VERSION ""

NS_ :

BS_:

BU_: Pi SlaveController

BO_ 10 BatterUniqueId: 8 SlaveController
 SG_ BatteryUniqueId_v2 : 0|64@1+ (1,0) [0|0] "" Vector__XXX

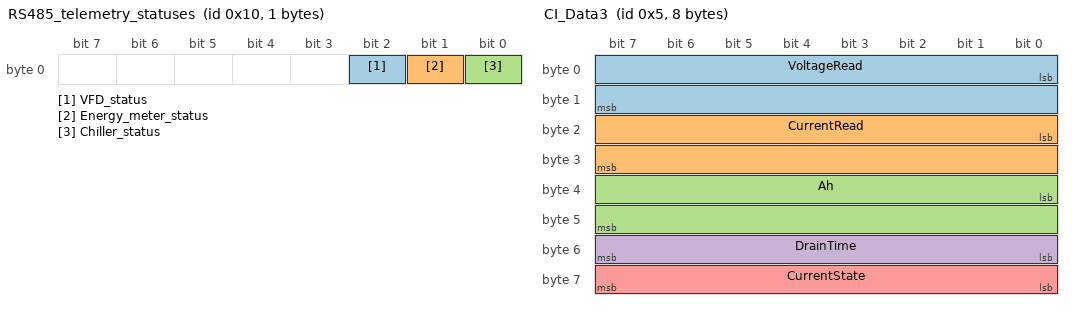
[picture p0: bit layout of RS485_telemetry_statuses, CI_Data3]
BO_ 16 RS485_telemetry_statuses: 1 SlaveController
 SG_ VFD_status : 2|1@1+ (1,0) [0|0] "" Vector__XXX
 SG_ Energy_meter_status : 1|1@1+ (1,0) [0|0] "" Vector__XXX
 SG_ Chiller_status : 0|1@1+ (1,0) [0|0] "" Vector__XXX

BO_ 5 CI_Data3: 8 SlaveController
 SG_ VoltageRead : 0|16@1+ (0.01,0) [0|0] "" Vector__XXX
 SG_ CurrentRead : 16|16@1+ (0.01,0) [0|0] "" Vector__XXX
 SG_ Ah : 32|16@1+ (0.01,0) [0|0] "" Vector__XXX
 SG_ DrainTime : 48|8@1+ (1,0) [0|0] "" Vector__XXX
 SG_ CurrentState : 56|8@1+ (1,0) [0|0] "" Vector__XXX

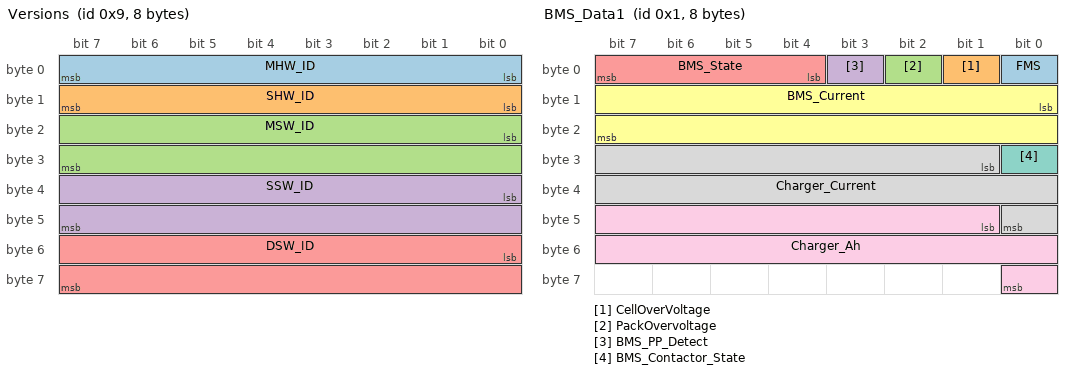
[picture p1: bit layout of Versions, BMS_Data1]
BO_ 9 Versions: 8 SlaveController
 SG_ MHW_ID : 0|8@1+ (1,0) [0|0] "" Vector__XXX
 SG_ SHW_ID : 8|8@1+ (1,0) [0|0] "" Vector__XXX
 SG_ MSW_ID : 16|16@1+ (1,0) [0|0] "" Vector__XXX
 SG_ SSW_ID : 32|16@1+ (1,0) [0|0] "" Vector__XXX
 SG_ DSW_ID : 48|16@1+ (1,0) [0|0] "" Vector__XXX

BO_ 1 BMS_Data1: 8 SlaveController
 SG_ FMS : 0|1@1+ (1,0) [0|0] "" Vector__XXX
 SG_ CellOverVoltage : 1|1@1+ (1,0) [0|0] "" Vector__XXX
 SG_ PackOvervoltage : 2|1@1+ (1,0) [0|0] "" Vector__XXX
 SG_ BMS_PP_Detect : 3|1@1+ (1,0) [0|0] "" Vector__XXX
 SG_ BMS_State : 4|4@1+ (1,0) [0|0] "" Vector__XXX
 SG_ BMS_Current : 8|16@1+ (0.1,-600) [0|0] "" Vector__XXX
 SG_ BMS_Contactor_State : 24|1@1+ (1,0) [0|0] "" Vector__XXX
 SG_ Charger_Current : 25|16@1+ (0.1,-600) [0|0] "" Vector__XXX
 SG_ Charger_Ah : 41|16@1+ (0.1,0) [0|0] "" Vector__XXX

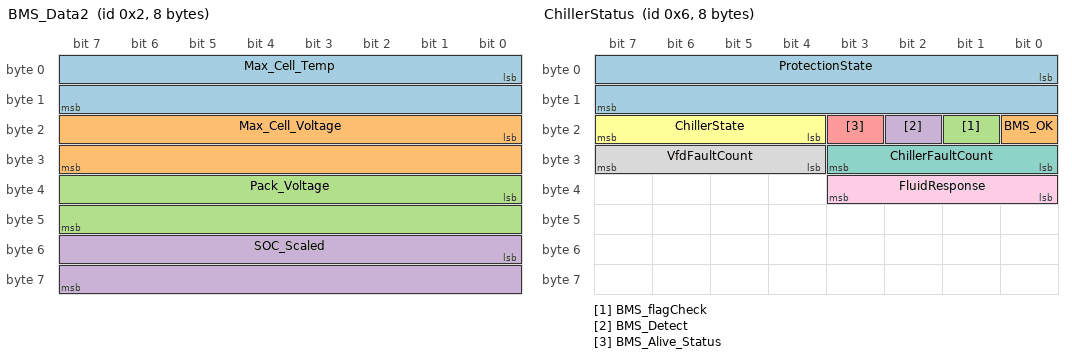
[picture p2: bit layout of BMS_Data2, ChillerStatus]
BO_ 2 BMS_Data2: 8 SlaveController
 SG_ Max_Cell_Temp : 0|16@1+ (0.01,-100) [0|0] "" Vector__XXX
 SG_ Max_Cell_Voltage : 16|16@1+ (0.0001,0) [0|0] "" Vector__XXX
 SG_ Pack_Voltage : 32|16@1+ (0.01,0) [0|0] "" Vector__XXX
 SG_ SOC_Scaled : 48|16@1+ (1.0,0) [0|0] "" Vector__XXX

BO_ 6 ChillerStatus: 8 SlaveController
 SG_ ProtectionState : 0|16@1+ (1,0) [0|0] "" Vector__XXX
 SG_ BMS_OK : 16|1@1+ (1,0) [0|0] "" Vector__XXX
 SG_ BMS_flagCheck : 17|1@1+ (1,0) [0|0] "" Vector__XXX
 SG_ BMS_Detect : 18|1@1+ (1,0) [0|0] "" Vector__XXX
 SG_ BMS_Alive_Status : 19|1@1+ (1,0) [0|0] "" Vector__XXX
 SG_ ChillerState : 20|4@1+ (1,0) [0|0] "" Vector__XXX
 SG_ ChillerFaultCount : 24|4@1+ (1,0) [0|0] "" Vector__XXX
 SG_ VfdFaultCount : 28|4@1+ (1,0) [0|0] "" Vector__XXX
 SG_ FluidResponse : 32|4@1+ (1,0) [0|0] "" Vector__XXX

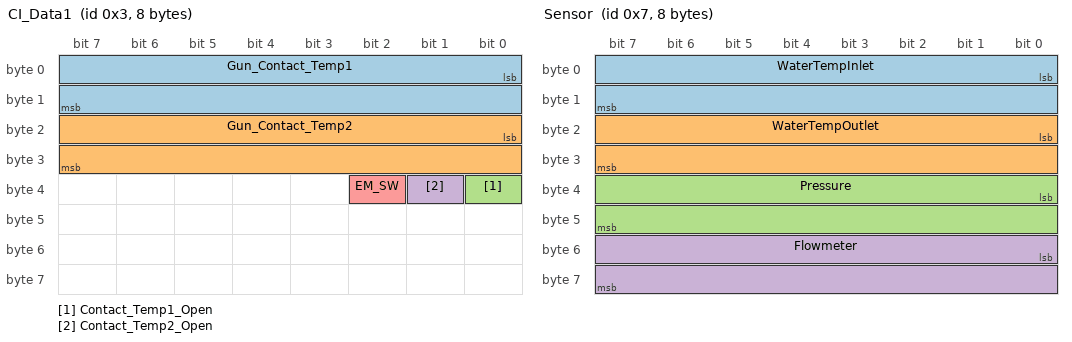
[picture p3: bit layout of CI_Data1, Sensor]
BO_ 3 CI_Data1: 8 SlaveController
 SG_ Gun_Contact_Temp1 : 0|16@1+ (0.01,-100) [0|0] "" Vector__XXX
 SG_ Gun_Contact_Temp2 : 16|16@1+ (0.01,-100) [0|0] "" Vector__XXX
 SG_ Contact_Temp1_Open : 32|1@1+ (1,0) [0|0] "" Vector__XXX
 SG_ Contact_Temp2_Open : 33|1@1+ (1,0) [0|0] "" Vector__XXX
 SG_ EM_SW : 34|1@1+ (1,0) [0|0] "" Vector__XXX

BO_ 4 CI_Data2: 8 SlaveController
 SG_ VoltageRef : 0|16@1+ (0.01,0) [0|0] "" Vector__XXX
 SG_ CurrentRef : 16|16@1+ (0.01,0) [0|0] "" Vector__XXX
 SG_ CC_ON : 32|1@1+ (1,0) [0|0] "" Vector__XXX
 SG_ DrainPump : 33|1@1+ (1,0) [0|0] "" Vector__XXX
 SG_ SolenoidA : 34|1@1+ (1,0) [0|0] "" Vector__XXX
 SG_ SolenoidB : 35|1@1+ (1,0) [0|0] "" Vector__XXX
 SG_ PositiveCont : 36|1@1+ (1,0) [0|0] "" Vector__XXX
 SG_ GunLock : 37|1@1+ (1,0) [0|0] "" Vector__XXX
 SG_ SolenoidC : 38|1@1+ (1,0) [0|0] "" Vector__XXX
 SG_ Precharge : 39|1@1+ (1,0) [0|0] "" Vector__XXX
 SG_ SolenoidA1 : 40|1@1+ (1,0) [0|0] "" Vector__XXX
 SG_ VFD_On : 41|1@1+ (1,0) [0|0] "" Vector__XXX
 SG_ Override : 42|1@1+ (1,0) [0|0] "" Vector__XXX
 SG_ AC_Cont : 43|1@1+ (1,0) [0|0] "" Vector__XXX
 SG_ SPD : 44|1@1+ (1,0) [0|0] "" Vector__XXX
 SG_ ELR : 45|1@1+ (1,0) [0|0] "" Vector__XXX
 SG_ VoltageRelay : 46|1@1+ (1,0) [0|0] "" Vector__XXX
 SG_ GunLockFB : 47|1@1+ (1,0) [0|0] "" Vector__XXX
 SG_ SolenoidB1 : 48|1@1+ (1,0) [0|0] "" Vector__XXX
 SG_ DisplayAlive : 49|1@1+ (1,0) [0|0] "" Vector__XXX
 SG_ MasterHearBeat : 50|1@1+ (1,0) [0|0] "" Vector__XXX
 SG_ SlaveHeartBeat : 51|1@1+ (1,0) [0|0] "" Vector__XXX

BO_ 7 Sensor: 8 SlaveController
 SG_ WaterTempInlet : 0|16@1+ (0.1,0) [0|0] "" Vector__XXX
 SG_ WaterTempOutlet : 16|16@1+ (0.1,0) [0|0] "" Vector__XXX
 SG_ Pressure : 32|16@1+ (0.1,0) [0|0] "" Vector__XXX
 SG_ Flowmeter : 48|16@1+ (0.1,0) [0|0] "" Vector__XXX

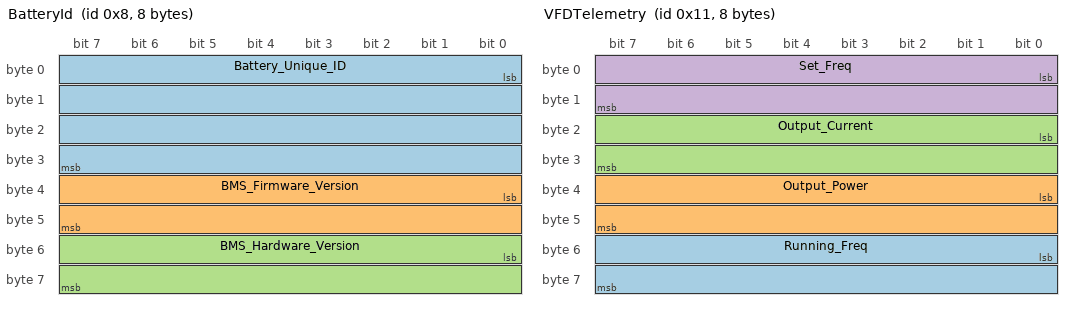
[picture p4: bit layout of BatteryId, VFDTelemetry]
BO_ 8 BatteryId: 8 SlaveController
 SG_ Battery_Unique_ID : 0|32@1+ (1,0) [0|0] "" Vector__XXX
 SG_ BMS_Firmware_Version : 32|16@1+ (1,0) [0|0] "" Vector__XXX
 SG_ BMS_Hardware_Version : 48|16@1+ (1,0) [0|0] "" Vector__XXX

BO_ 17 VFDTelemetry: 8 Pi
 SG_ Running_Freq : 48|16@1+ (0.01,0) [0|0] "Hz" Vector__XXX
 SG_ Output_Power : 32|16@1+ (0.1,0) [0|0] "kW" Vector__XXX
 SG_ Output_Current : 16|16@1+ (0.1,0) [0|0] "A" Vector__XXX
 SG_ Set_Freq : 0|16@1+ (0.01,0) [0|0] "Hz" Vector__XXX

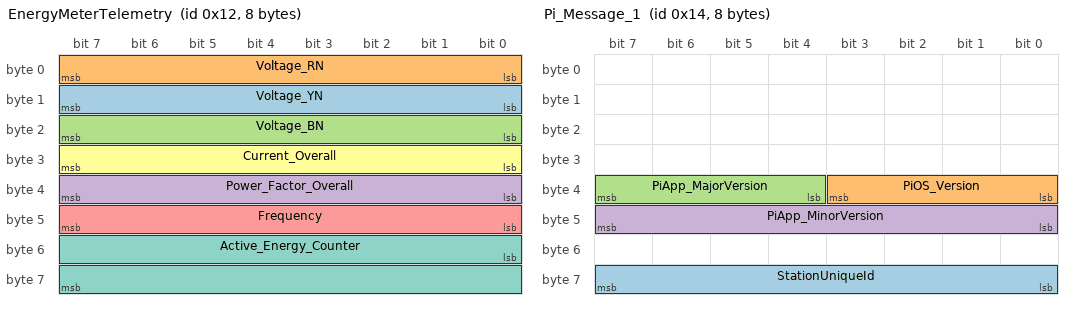
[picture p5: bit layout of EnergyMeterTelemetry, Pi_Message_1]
BO_ 18 EnergyMeterTelemetry: 8 Pi
 SG_ Voltage_YN : 8|8@1+ (2,0) [0|0] "V" Vector__XXX
 SG_ Voltage_RN : 0|8@1+ (2,0) [0|0] "V" Vector__XXX
 SG_ Voltage_BN : 16|8@1+ (2,0) [0|0] "V" Vector__XXX
 SG_ Power_Factor_Overall : 32|8@1- (0.01,0) [0|0] "" Vector__XXX
 SG_ Frequency : 40|8@1- (0.01,50) [0|0] "Hz" Vector__XXX
 SG_ Current_Overall : 24|8@1+ (1,0) [0|0] "A" Vector__XXX
 SG_ Active_Energy_Counter : 48|16@1- (1,0) [0|0] "kWh" Vector__XXX

BO_ 19 ChillerTelemetry: 8 Pi
 SG_ SV_On : 58|1@1+ (1,0) [0|0] "" Vector__XXX
 SG_ Pump_On : 57|1@1+ (1,0) [0|0] "" Vector__XXX
 SG_ Cond_On : 60|1@1+ (1,0) [0|0] "" Vector__XXX
 SG_ Compressor_On : 56|1@1+ (1,0) [0|0] "" Vector__XXX
 SG_ Alarm_On : 59|1@1+ (1,0) [0|0] "" Vector__XXX
 SG_ System_Standby : 52|1@1+ (1,0) [0|0] "" Vector__XXX
 SG_ Low_Liquid_Level_Fault : 48|1@1+ (1,0) [0|0] "" Vector__XXX
 SG_ Liquid_Line_High_Temp_Fault : 49|1@1+ (1,0) [0|0] "" Vector__XXX
 SG_ High_Temp_Trip_Fault : 50|1@1+ (1,0) [0|0] "" Vector__XXX
 SG_ AFT_Fault : 51|1@1+ (1,0) [0|0] "" Vector__XXX
 SG_ Single_Phase_Prevention_Fault : 41|1@1+ (1,0) [0|0] "" Vector__XXX
 SG_ Remote_Fault : 46|1@1+ (1,0) [0|0] "" Vector__XXX
 SG_ Pump_Overload_Fault : 40|1@1+ (1,0) [0|0] "" Vector__XXX
 SG_ Low_Pressure_Fault : 44|1@1+ (1,0) [0|0] "" Vector__XXX
 SG_ High_Pressure_Fault : 43|1@1+ (1,0) [0|0] "" Vector__XXX
 SG_ FLS_Fault : 45|1@1+ (1,0) [0|0] "" Vector__XXX
 SG_ Compressor_Overload_Fault : 42|1@1+ (1,0) [0|0] "" Vector__XXX
 SG_ Room_Temp_Probe_LT_Fault : 35|1@1+ (1,0) [0|0] "" Vector__XXX
 SG_ Room_Temp_Probe_HT_Fault : 34|1@1+ (1,0) [0|0] "" Vector__XXX
 SG_ Room_Temp_Probe_Fail : 32|1@1+ (1,0) [0|0] "" Vector__XXX
 SG_ Liquid_Line_Probe_Fail : 36|1@1+ (1,0) [0|0] "" Vector__XXX
 SG_ AFT_Probe_Fail : 33|1@1+ (1,0) [0|0] "" Vector__XXX
 SG_ Liquid_Temp : 0|16@1- (0.1,0) [0|0] "C" Vector__XXX
 SG_ AFT_Temp : 16|16@1- (0.1,0) [0|0] "C" Vector__XXX

 BO_ 20 Pi_Message_1: 8 Vector__XXX
 SG_ StationUniqueId : 56|8@1+ (1,0) [0|0] "" Vector__XXX
 SG_ PiOS_Version : 32|4@1+ (1,0) [0|0] "" Vector__XXX
 SG_ PiApp_MajorVersion : 36|4@1+ (1,0) [0|0] "" Vector__XXX
 SG_ PiApp_MinorVersion : 40|8@1+ (1,0) [0|0] "" Vector__XXX

BA_DEF_  "BusType" STRING ;
BA_DEF_DEF_  "BusType" "";
BA_ "BusType" "CAN";
